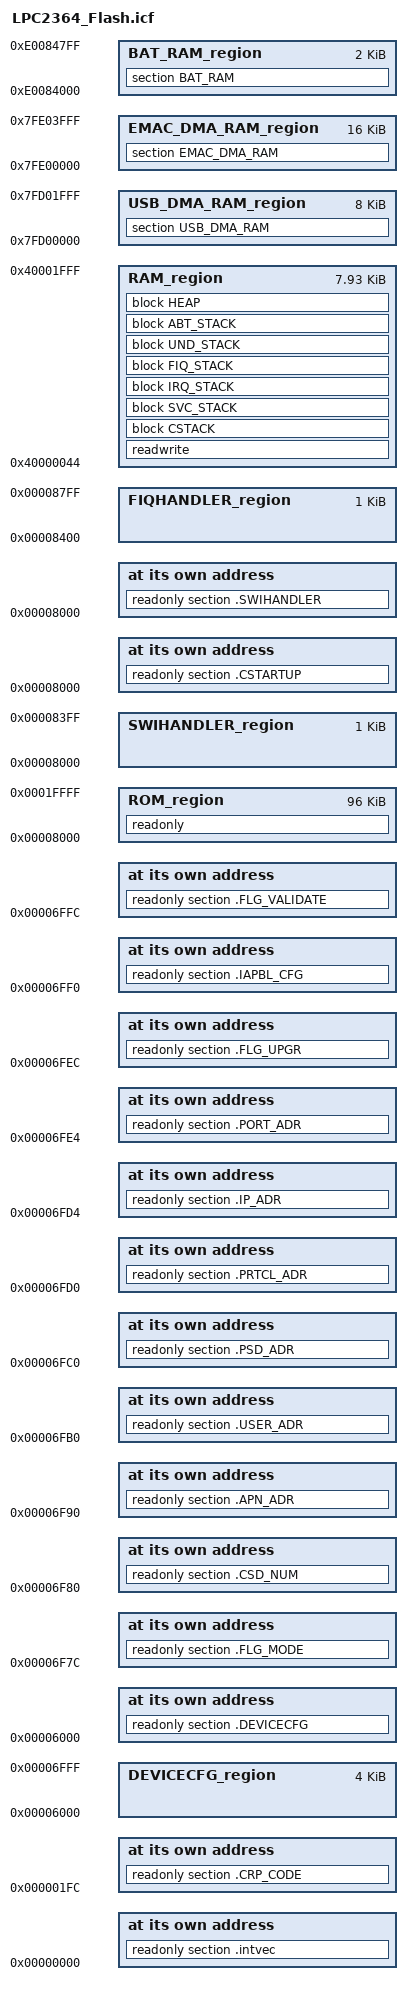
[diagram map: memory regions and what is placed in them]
/*###ICF### Section handled by ICF editor, don't touch! ****/
/*-Editor annotation file-*/
/* IcfEditorFile="$TOOLKIT_DIR$\config\ide\IcfEditor\a_v1_0.xml" */

/*-Specials-*/
define symbol __ICFEDIT_intvec_start__   = 0x00000000;
define symbol __ICFEDIT_cstartup_start__ = 0x00008000;

define symbol _CRP_ADR__ = 0x000001FC;

define symbol _FLG_VALIDATE__ = 0x00006FFC;
define symbol _IAPBL_CFG__    = 0x00006FF0;
define symbol _FLG_UPGR__     = 0x00006FEC;

define symbol _FLG_MODE__  = 0x00006F7C;
define symbol _CSD_NUM__   = 0x00006F80;
define symbol _APN_ADR__   = 0x00006F90;
define symbol _USER_ADR__  = 0x00006FB0;
define symbol _PSD_ADR__   = 0x00006FC0;
define symbol _PRTCL_ADR__ = 0x00006FD0;
define symbol _IP_ADR__    = 0x00006FD4;
define symbol _PORT_ADR__  = 0x00006FE4;

/*-Memory Regions-*/
define symbol __ICFEDIT_region_ROM_start__ = 0x00008000;
define symbol __ICFEDIT_region_ROM_end__   = 0x0001FFFF;
define symbol __ICFEDIT_region_RAM_start__ = 0x40000044;
define symbol __ICFEDIT_region_RAM_end__   = 0x40001FFF;

/*-DEVICECFG Memory Regions-*/
define symbol _region_DEVICECFG_start__ = 0x00006000;
define symbol _region_DEVICECFG_end__   = 0x00006FFF;

/*-Specials Memory Regions-*/
define symbol _region_SWIHANDLER_start__ = 0x00008000;
define symbol _region_SWIHANDLER_end__   = 0x000083FF;
define symbol _region_FIQHANDLER_start__ = 0x00008400;
define symbol _region_FIQHANDLER_end__   = 0x000087FF;

/*-USB Memory Regions-*/
define symbol __region_USB_DMA_RAM_start__ = 0x7FD00000;
define symbol __region_USB_DMA_RAM_end__   = 0x7FD01FFF;

/*-EMAC Memory Regions-*/
define symbol __region_EMAC_DMA_RAM_start__ = 0x7FE00000;
define symbol __region_EMAC_DMA_RAM_end__   = 0x7FE03FFF;

/*-BATRAM Memory Regions-*/
define symbol __region_BAT_RAM_start__ = 0xE0084000;
define symbol __region_BAT_RAM_end__   = 0xE00847FF;


/*-Sizes-*/
define symbol __ICFEDIT_size_cstack__   = 0x900;
define symbol __ICFEDIT_size_svcstack__ = 0x10;
define symbol __ICFEDIT_size_irqstack__ = 0x200;
define symbol __ICFEDIT_size_fiqstack__ = 0x40;
define symbol __ICFEDIT_size_undstack__ = 0x10;
define symbol __ICFEDIT_size_abtstack__ = 0x10;
define symbol __ICFEDIT_size_heap__     = 0x100;
/**** End of ICF editor section. ###ICF###*/


define memory mem with size = 4G;
define region ROM_region = mem:[from __ICFEDIT_region_ROM_start__  to __ICFEDIT_region_ROM_end__];
define region RAM_region = mem:[from __ICFEDIT_region_RAM_start__  to __ICFEDIT_region_RAM_end__];


define region DEVICECFG_region = mem:[from _region_DEVICECFG_start__  to _region_DEVICECFG_end__];

define region SWIHANDLER_region = mem:[from _region_SWIHANDLER_start__  to _region_SWIHANDLER_end__];
define region FIQHANDLER_region = mem:[from _region_FIQHANDLER_start__  to _region_FIQHANDLER_end__];

define region USB_DMA_RAM_region = mem:[from __region_USB_DMA_RAM_start__    to __region_USB_DMA_RAM_end__];
define region EMAC_DMA_RAM_region = mem:[from __region_EMAC_DMA_RAM_start__  to __region_EMAC_DMA_RAM_end__];
define region BAT_RAM_region = mem:[from __region_BAT_RAM_start__  to __region_BAT_RAM_end__];

define block CSTACK    with alignment = 8, size = __ICFEDIT_size_cstack__   { };
define block SVC_STACK with alignment = 8, size = __ICFEDIT_size_svcstack__ { };
define block IRQ_STACK with alignment = 8, size = __ICFEDIT_size_irqstack__ { };
define block FIQ_STACK with alignment = 8, size = __ICFEDIT_size_fiqstack__ { };
define block UND_STACK with alignment = 8, size = __ICFEDIT_size_undstack__ { };
define block ABT_STACK with alignment = 8, size = __ICFEDIT_size_abtstack__ { };
define block HEAP      with alignment = 8, size = __ICFEDIT_size_heap__     { };


/* Place code at a fixed address */
place at address mem:__ICFEDIT_intvec_start__ { readonly section .intvec };
place at address mem:__ICFEDIT_cstartup_start__ { readonly section .CSTARTUP };

place at address mem:_CRP_ADR__ { readonly section .CRP_CODE };
place at address mem:_IAPBL_CFG__ { readonly section .IAPBL_CFG };
place at address mem:_FLG_UPGR__ { readonly section .FLG_UPGR };
place at address mem:_FLG_VALIDATE__{ readonly section .FLG_VALIDATE };
place at address mem:_FLG_MODE__{ readonly section .FLG_MODE };
place at address mem:_CSD_NUM__{ readonly section .CSD_NUM };
place at address mem:_APN_ADR__{ readonly section .APN_ADR };
place at address mem:_USER_ADR__{ readonly section .USER_ADR };
place at address mem:_PSD_ADR__{ readonly section .PSD_ADR };
place at address mem:_PRTCL_ADR__{ readonly section .PRTCL_ADR };
place at address mem:_IP_ADR__{ readonly section .IP_ADR };
place at address mem:_PORT_ADR__{ readonly section .PORT_ADR };


place at address mem: _region_DEVICECFG_start__ { readonly section .DEVICECFG };
place at address mem: _region_SWIHANDLER_start__ { readonly section .SWIHANDLER };


initialize by copy { readwrite };
do not initialize  { section .noinit };
do not initialize  { section .DEVICECFG };
do not initialize  { section .CRP_CODE };
do not initialize  { section .IAPBL_CFG };
do not initialize  { section .FLG_UPGR };
do not initialize  { section .FLG_VALIDATE };
do not initialize  { section .FLG_MODE };
do not initialize  { section .CSD_NUM };
do not initialize  { section .APN_ADR };
do not initialize  { section .USER_ADR };
do not initialize  { section .PSD_ADR };
do not initialize  { section .PRTCL_ADR };
do not initialize  { section .IP_ADR };
do not initialize  { section .PORT_ADR };

do not initialize  { section USB_DMA_RAM };
do not initialize  { section EMAC_DMA_RAM };
do not initialize  { section BAT_RAM };

place in ROM_region   { readonly };
place in RAM_region   { readwrite,
                        block CSTACK, block SVC_STACK, block IRQ_STACK, block FIQ_STACK,
                        block UND_STACK, block ABT_STACK, block HEAP };
                        
place in USB_DMA_RAM_region   { section USB_DMA_RAM };
place in EMAC_DMA_RAM_region  { section EMAC_DMA_RAM };
place in BAT_RAM_region  { section BAT_RAM };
